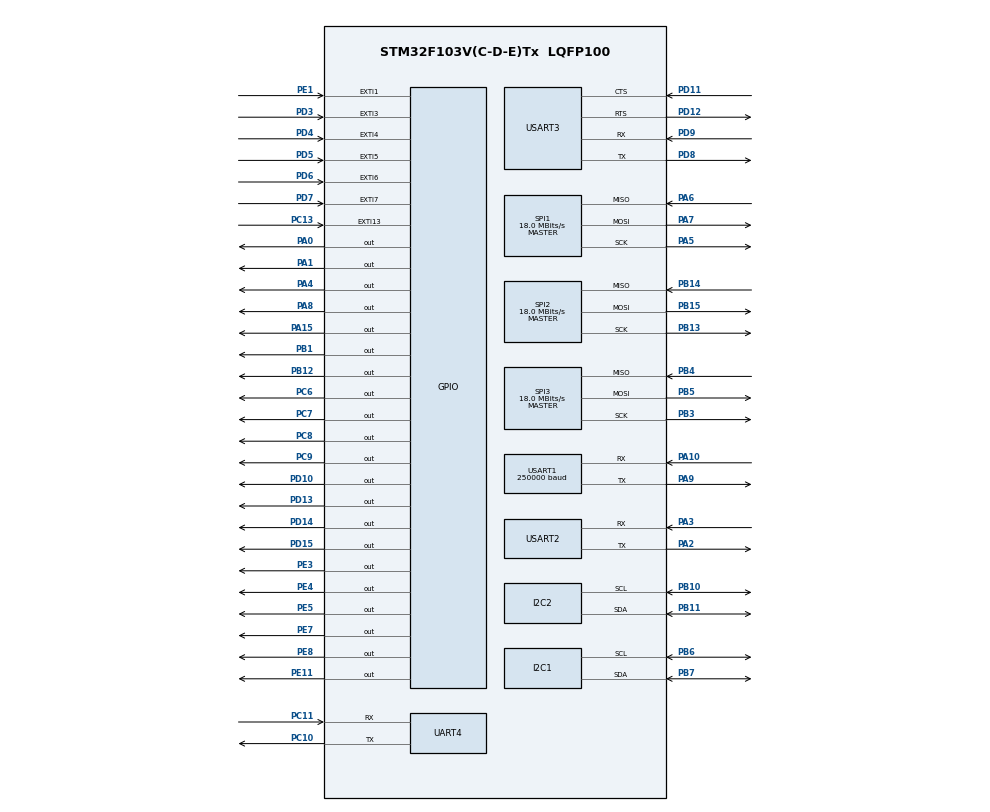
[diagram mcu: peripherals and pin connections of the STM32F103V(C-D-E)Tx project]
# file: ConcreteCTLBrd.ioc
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Dma.Request0=USART2_RX
Dma.USART2_RX.0.Direction=DMA_PERIPH_TO_MEMORY
Dma.USART2_RX.0.Instance=DMA1_Channel6
Dma.USART2_RX.0.MemDataAlignment=DMA_MDATAALIGN_BYTE
Dma.USART2_RX.0.MemInc=DMA_MINC_ENABLE
Dma.USART2_RX.0.Mode=DMA_NORMAL
Dma.USART2_RX.0.PeriphDataAlignment=DMA_PDATAALIGN_BYTE
Dma.USART2_RX.0.PeriphInc=DMA_PINC_DISABLE
Dma.USART2_RX.0.Priority=DMA_PRIORITY_HIGH
FREERTOS.INCLUDE_xSemaphoreGetMutexHolder=1
FREERTOS.INCLUDE_xTaskGetCurrentTaskHandle=1
FREERTOS.INCLUDE_xTaskGetHandle=1
FREERTOS.Tasks01=defaultTask,24,128,StartDefaultTask,Default,NULL,Dynamic,NULL,NULL
FREERTOS.configTOTAL_HEAP_SIZE=12072
Mcu.Family=STM32F1
Mcu.Name=STM32F103V(C-D-E)Tx
Mcu.Package=LQFP100
NVIC.DMA1_Channel6_IRQn=true\:5\:0\:false\:false\:true\:true\:false\:true
NVIC.PriorityGroup=NVIC_PRIORITYGROUP_4
OSC_IN.Mode=HSE-External-Oscillator
OSC_IN.Signal=RCC_OSC_IN
OSC_IN.Stacked=true
OSC_OUT.Mode=HSE-External-Oscillator
OSC_OUT.Signal=RCC_OSC_OUT
OSC_OUT.Stacked=true
PA0-WKUP.Signal=GPIO_Output
PA1.Signal=GPIO_Output
PA1.Stacked=true
PA10.Mode=Asynchronous
PA10.Signal=USART1_RX
PA10.Stacked=true
PA13.Mode=Serial_Wire
PA13.Signal=SYS_JTMS-SWDIO
PA13.Stacked=true
PA14.Mode=Serial_Wire
PA14.Signal=SYS_JTCK-SWCLK
PA14.Stacked=true
PA15.GPIO_Speed=GPIO_SPEED_FREQ_MEDIUM
PA15.Signal=GPIO_Output
PA15.Stacked=true
PA2.Mode=Asynchronous
PA2.Signal=USART2_TX
PA2.Stacked=true
PA3.Mode=Asynchronous
PA3.Signal=USART2_RX
PA3.Stacked=true
PA4.GPIO_Speed=GPIO_SPEED_FREQ_HIGH
PA4.Signal=GPIO_Output
PA4.Stacked=true
PA5.Mode=Full_Duplex_Master
PA5.Signal=SPI1_SCK
PA5.Stacked=true
PA6.Mode=Full_Duplex_Master
PA6.Signal=SPI1_MISO
PA6.Stacked=true
PA7.Mode=Full_Duplex_Master
PA7.Signal=SPI1_MOSI
PA7.Stacked=true
PA8.Signal=GPIO_Output
PA9.Mode=Asynchronous
PA9.Signal=USART1_TX
PA9.Stacked=true
PB1.Signal=GPIO_Output
PB10.Mode=I2C
PB10.Signal=I2C2_SCL
PB10.Stacked=true
PB11.Mode=I2C
PB11.Signal=I2C2_SDA
PB11.Stacked=true
PB12.Signal=GPIO_Output
PB12.Stacked=true
PB13.Mode=Full_Duplex_Master
PB13.Signal=SPI2_SCK
PB13.Stacked=true
PB14.Mode=Full_Duplex_Master
PB14.Signal=SPI2_MISO
PB14.Stacked=true
PB15.Mode=Full_Duplex_Master
PB15.Signal=SPI2_MOSI
PB15.Stacked=true
PB3.Mode=Full_Duplex_Master
PB3.Signal=SPI3_SCK
PB4.Mode=Full_Duplex_Master
PB4.Signal=SPI3_MISO
PB5.Mode=Full_Duplex_Master
PB5.Signal=SPI3_MOSI
PB6.Mode=I2C
PB6.Signal=I2C1_SCL
PB6.Stacked=true
PB7.Mode=I2C
PB7.Signal=I2C1_SDA
PB7.Stacked=true
PC10.Mode=Asynchronous
PC10.Signal=UART4_TX
PC10.Stacked=true
PC11.Mode=Asynchronous
PC11.Signal=UART4_RX
PC11.Stacked=true
PC13-TAMPER-RTC.GPIO_ModeDefaultEXTI=GPIO_MODE_IT_FALLING
PC13-TAMPER-RTC.GPIO_PuPd=GPIO_PULLUP
PC13-TAMPER-RTC.Signal=GPXTI13
PC13-TAMPER-RTC.Stacked=true
PC14-OSC32_IN.Mode=LSE-External-Oscillator
PC14-OSC32_IN.Signal=RCC_OSC32_IN
PC14-OSC32_IN.Stacked=true
PC15-OSC32_OUT.Mode=LSE-External-Oscillator
PC15-OSC32_OUT.Signal=RCC_OSC32_OUT
PC15-OSC32_OUT.Stacked=true
PC6.Signal=GPIO_Output
PC7.Signal=GPIO_Output
PC8.Signal=GPIO_Output
PC9.Signal=GPIO_Output
PD10.Signal=GPIO_Output
PD10.Stacked=true
PD11.Mode=CTS_RTS
PD11.Signal=USART3_CTS
PD11.Stacked=true
PD12.Mode=CTS_RTS
PD12.Signal=USART3_RTS
PD12.Stacked=true
PD13.Signal=GPIO_Output
PD14.Signal=GPIO_Output
PD15.Signal=GPIO_Output
PD3.Signal=GPXTI3
PD3.Stacked=true
PD4.Signal=GPXTI4
PD4.Stacked=true
PD5.Signal=GPXTI5
PD5.Stacked=true
PD6.Signal=GPXTI6
PD6.Stacked=true
PD7.Signal=GPXTI7
PD7.Stacked=true
PD8.Mode=Asynchronous
PD8.Signal=USART3_TX
PD8.Stacked=true
PD9.Mode=Asynchronous
PD9.Signal=USART3_RX
PD9.Stacked=true
PE1.Signal=GPXTI1
PE11.Signal=GPIO_Output
PE3.Signal=GPIO_Output
PE3.Stacked=true
PE4.Signal=GPIO_Output
PE4.Stacked=true
PE5.Signal=GPIO_Output
PE5.Stacked=true
PE7.GPIO_Speed=GPIO_SPEED_FREQ_HIGH
PE7.PinState=GPIO_PIN_SET
PE7.Signal=GPIO_Output
PE7.Stacked=true
PE8.GPIO_Speed=GPIO_SPEED_FREQ_HIGH
PE8.PinState=GPIO_PIN_SET
PE8.Signal=GPIO_Output
PE8.Stacked=true
ProjectManager.HeapSize=0x200
ProjectManager.StackSize=0x400
ProjectManager.TargetToolchain=Other Toolchains (GPDSC)
RCC.AHBFreq_Value=72000000
RCC.APB1CLKDivider=RCC_HCLK_DIV2
RCC.APB1Freq_Value=36000000
RCC.APB1TimFreq_Value=72000000
RCC.APB2Freq_Value=72000000
RCC.APB2TimFreq_Value=72000000
RCC.HCLKFreq_Value=72000000
RCC.PLLMUL=RCC_PLL_MUL9
RCC.PLLSourceVirtual=RCC_PLLSOURCE_HSE
RCC.SYSCLKFreq_VALUE=72000000
RCC.SYSCLKSource=RCC_SYSCLKSOURCE_PLLCLK
RCC.USBFreq_Value=48000000
RCC.USBPrescaler=RCC_USBCLKSOURCE_PLL_DIV1_5
SPI1.BaudRatePrescaler=SPI_BAUDRATEPRESCALER_4
SPI1.CalculateBaudRate=18.0 MBits/s
SPI1.Direction=SPI_DIRECTION_2LINES
SPI1.Mode=SPI_MODE_MASTER
SPI1.VirtualType=VM_MASTER
SPI2.BaudRatePrescaler=SPI_BAUDRATEPRESCALER_2
SPI2.CalculateBaudRate=18.0 MBits/s
SPI2.Direction=SPI_DIRECTION_2LINES
SPI2.Mode=SPI_MODE_MASTER
SPI2.VirtualType=VM_MASTER
SPI3.CalculateBaudRate=18.0 MBits/s
SPI3.Direction=SPI_DIRECTION_2LINES
SPI3.Mode=SPI_MODE_MASTER
SPI3.VirtualType=VM_MASTER
UART4.VirtualMode=Asynchronous
USART1.BaudRate=250000
USART1.VirtualMode=VM_ASYNC
USART2.VirtualMode=VM_ASYNC
USART3.VirtualMode=VM_ASYNC
VP_FREERTOS_VS_CMSIS_V2.Mode=CMSIS_V2
VP_TIM3_VS_ClockSourceINT.Mode=Internal
board=custom

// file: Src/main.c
/* USER CODE BEGIN Header */
/**
  ******************************************************************************
  * @file           : main.c
  * @brief          : Main program body
  ******************************************************************************
  * @attention
  *
  * <h2><center>&copy; Copyright (c) 2021 STMicroelectronics.
  * All rights reserved.</center></h2>
  *
  * This software component is licensed by ST under Ultimate Liberty license
  * SLA0044, the "License"; You may not use this file except in compliance with
  * the License. You may obtain a copy of the License at:
  *                             www.st.com/SLA0044
  *
  ******************************************************************************
  */
/* USER CODE END Header */
#include "main.h"
//#include "Middlewares/Third_Party/FreeRTOS/Source/CMSIS_RTOS_V2/cmsis_os.h"
#include "dma.h"
#include "i2c.h"
#include "spi.h"
#include "tim.h"
#include "usart.h"
#include "gpio.h"

/* USER CODE BEGIN Includes */
#include "User/Inc/Cmd_Proc.h"
#include "User/Inc/Debug.h"
/* USER CODE END Includes */

void SystemClock_Config(void);
void MX_FREERTOS_Init(void);

int main(void)
{

  /* MCU Configuration--------------------------------------------------------*/

  /* Reset of all peripherals, Initializes the Flash interface and the Systick. */

  LL_APB2_GRP1_EnableClock(LL_APB2_GRP1_PERIPH_AFIO);
  LL_APB1_GRP1_EnableClock(LL_APB1_GRP1_PERIPH_PWR);

  NVIC_SetPriorityGrouping(NVIC_PRIORITYGROUP_4);

  /* System interrupt init*/
  /* PendSV_IRQn interrupt configuration */
  NVIC_SetPriority(PendSV_IRQn, NVIC_EncodePriority(NVIC_GetPriorityGrouping(),15, 0));
  /* SysTick_IRQn interrupt configuration */
  NVIC_SetPriority(SysTick_IRQn, NVIC_EncodePriority(NVIC_GetPriorityGrouping(),15, 0));

  /** NOJTAG: JTAG-DP Disabled and SW-DP Enabled
  */
  LL_GPIO_AF_Remap_SWJ_NOJTAG();

  /* Configure the system clock */
  SystemClock_Config();

  /* Initialize all configured peripherals */
  MX_GPIO_Init();
  MX_DMA_Init();
  MX_USART1_UART_Init();
  MX_USART2_UART_Init();
  MX_SPI1_Init();
  MX_I2C1_Init();
  MX_SPI2_Init();
  MX_I2C2_Init();
  MX_USART3_UART_Init();
  MX_UART4_Init();
  MX_TIM3_Init();
  MX_SPI3_Init();
  /* USER CODE BEGIN 2 */
	CMD_IN_UART2_Init();	//初始化串口和DMA模块

  /* USER CODE END 2 */

  /* Init scheduler */
  osKernelInitialize();  /* Call init function for freertos objects (in freertos.c) */
  MX_FREERTOS_Init();
  /* Start scheduler */
  osKernelStart();

  /* We should never get here as control is now taken by the scheduler */
  /* Infinite loop */
  while (1)
  {

  }
}

void SystemClock_Config(void)
{
  LL_FLASH_SetLatency(LL_FLASH_LATENCY_2);
  while(LL_FLASH_GetLatency()!= LL_FLASH_LATENCY_2)
  {
  }
  LL_RCC_HSE_Enable();

   /* Wait till HSE is ready */
  while(LL_RCC_HSE_IsReady() != 1)
  {

  }
  LL_RCC_PLL_ConfigDomain_SYS(LL_RCC_PLLSOURCE_HSE_DIV_1, LL_RCC_PLL_MUL_9);
  LL_RCC_PLL_Enable();

   /* Wait till PLL is ready */
  while(LL_RCC_PLL_IsReady() != 1)
  {

  }
  LL_RCC_SetAHBPrescaler(LL_RCC_SYSCLK_DIV_1);
  LL_RCC_SetAPB1Prescaler(LL_RCC_APB1_DIV_2);
  LL_RCC_SetAPB2Prescaler(LL_RCC_APB2_DIV_1);
  LL_RCC_SetSysClkSource(LL_RCC_SYS_CLKSOURCE_PLL);

   /* Wait till System clock is ready */
  while(LL_RCC_GetSysClkSource() != LL_RCC_SYS_CLKSOURCE_STATUS_PLL)
  {

  }
  LL_Init1msTick(72000000);
  LL_SetSystemCoreClock(72000000);
}

void Error_Handler(void)
{
  __disable_irq();
  while (1)
  {
  }
}

/************************ (C) COPYRIGHT STMicroelectronics *****END OF FILE****/

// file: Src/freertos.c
/* USER CODE BEGIN Header */
/**
  ******************************************************************************
  * File Name          : freertos.c
  * Description        : Code for freertos applications
  ******************************************************************************
  * @attention
  *
  * <h2><center>&copy; Copyright (c) 2021 STMicroelectronics.
  * All rights reserved.</center></h2>
  *
  * This software component is licensed by ST under Ultimate Liberty license
  * SLA0044, the "License"; You may not use this file except in compliance with
  * the License. You may obtain a copy of the License at:
  *                             www.st.com/SLA0044
  *
  ******************************************************************************
  */
/* USER CODE END Header */

#include "FreeRTOS.h"
#include "task.h"
#include "main.h"
#include "Middlewares/Third_Party/FreeRTOS/Source/CMSIS_RTOS_V2/cmsis_os.h"

/* Definitions for defaultTask */
osThreadId_t defaultTaskHandle;
const osThreadAttr_t defaultTask_attributes = {
  .name = "defaultTask",
  .stack_size = 128 * 4,
  .priority = (osPriority_t) osPriorityNormal,
};

void StartDefaultTask(void *argument);

void MX_FREERTOS_Init(void); /* (MISRA C 2004 rule 8.1) */

void MX_FREERTOS_Init(void) {

  /* Create the thread(s) */
  /* creation of defaultTask */
  defaultTaskHandle = osThreadNew(StartDefaultTask, NULL, &defaultTask_attributes);

}

void StartDefaultTask(void *argument)
{
  for(;;)
  {
    osDelay(1);
  }
}

/************************ (C) COPYRIGHT STMicroelectronics *****END OF FILE****/
